# R7FA6T3BB register map
Vendor: Renesas Electronics Corporation; Series: RA6; File version: 1.30.00
CPU: CM33 r0p4, little endian, MPU, FPU, VTOR, 4 interrupt priority bits, 96 interrupts
Registers are 32-bit, read-write, reset 0x0 unless marked. A register's access mark holds for its fields unless they carry their own. Offsets are from the block's base; [hi:lo] are bit positions; 'fields as' and 'values as' point back to an identical list.

## MSTP — Module Stop Control
Base 0x40084000
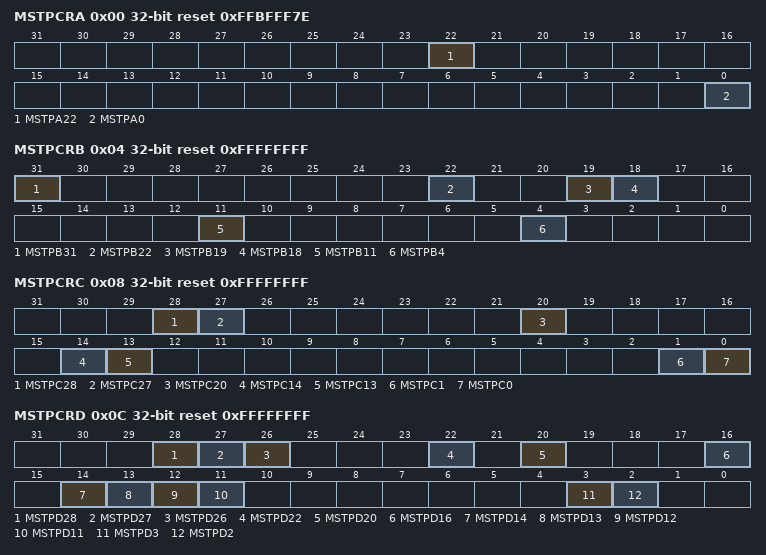
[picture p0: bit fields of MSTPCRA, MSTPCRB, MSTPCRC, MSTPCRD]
0x00 MSTPCRA reset 0xFFBFFF7E — Module Stop Control Register A
  [22] MSTPA22 — DMA Controller/Data Transfer Controller Module Stop
    0=Cancel the module-stop state; 1=Enter the module-stop state
  [0] MSTPA0 — SRAM0 Module Stop
    values as MSTPA22
0x04 MSTPCRB reset 0xFFFFFFFF — Module Stop Control Register B
  [all] fields
    values as MSTPCRA.MSTPA22
  [31] MSTPB31 — Serial Communication Interface 0 Module Stop
  [22] MSTPB22 — Serial Communication Interface 9 Module Stop
  [19] MSTPB19 — Serial Peripheral Interface 0 Module Stop
  [18] MSTPB18 — Serial Peripheral Interface 1 Module Stop
  [11] MSTPB11 — Universal Serial Bus 2.0 FS Interface 0 Module Stop
  [4] MSTPB4 — I3C Bus Interface 0 Module Stop
0x08 MSTPCRC reset 0xFFFFFFFF — Module Stop Control Register C
  [all] fields
    values as MSTPCRA.MSTPA22
  [28] MSTPC28 — Random Number Generator Module Stop
  [27] MSTPC27 — CANFD Module Stop
  [20] MSTPC20 — Trigonometric Function Unit Module Stop
  [14] MSTPC14 — Event Link Controller Module Stop
  [13] MSTPC13 — Data Operation Circuit Module Stop
  [1] MSTPC1 — Cyclic Redundancy Check Calculator Module Stop
  [0] MSTPC0 — Clock Frequency Accuracy Measurement Circuit Module Stop
0x0C MSTPCRD reset 0xFFFFFFFF — Module Stop Control Register D
  [all] fields
    values as MSTPCRA.MSTPA22
  [28] MSTPD28 — High-Speed Analog Comparator 0 Module Stop
  [27] MSTPD27 — High-Speed Analog Comparator 1 Module Stop
  [26] MSTPD26 — High-Speed Analog Comparator 2 Module Stop
  [22] MSTPD22 — Temperature Sensor Module Stop
  [20] MSTPD20 — 12-bit D/A Converter Module Stop
  [16] MSTPD16 — 12-bit A/D Converter 0 Module Stop
  [14] MSTPD14 — Port Output Enable for GPT Group A Module Stop
  [13] MSTPD13 — Port Output Enable for GPT Group B Module Stop
  [12] MSTPD12 — Port Output Enable for GPT Group C Module Stop
  [11] MSTPD11 — Port Output Enable for GPT Group D Module Stop
  [3] MSTPD3 — Low Power Asynchronous General Purpose Timer 0 Module Stop
  [2] MSTPD2 — Low Power Asynchronous General Purpose Timer 1 Module Stop
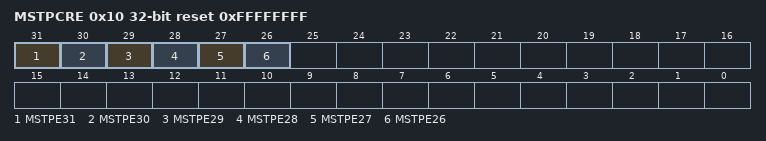
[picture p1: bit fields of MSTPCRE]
0x10 MSTPCRE reset 0xFFFFFFFF — Module Stop Control Register E
  [all] fields
    values as MSTPCRA.MSTPA22
  [31] MSTPE31 — GPT0 Module Stop
  [30] MSTPE30 — GPT1 Module Stop
  [29] MSTPE29 — GPT2 Module Stop
  [28] MSTPE28 — GPT3 Module Stop
  [27] MSTPE27 — GPT4 Module Stop
  [26] MSTPE26 — GPT5 Module Stop

## TSN — Temperature Sensor
Base 0x400F3000
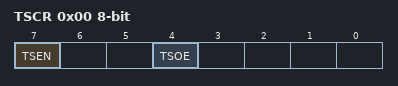
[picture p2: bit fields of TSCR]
0x00 TSCR 8-bit — Temperature Sensor Control Register
  [7] TSEN — Temperature Sensor Enable
    0=Stop the temperature sensor; 1=Start the temperature sensor
  [4] TSOE — Temperature Sensor Output Enable
    0=Disable output from the temperature sensor to the ADC12; 1=Enable output from the temperature sensor to the ADC12

## ACMPHS0 — High-Speed Analog Comparator 0
Base 0x400F4000
Same registers: ACMPHS1 0x400F4100, ACMPHS2 0x400F4200
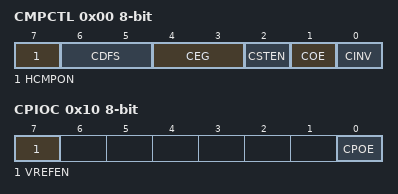
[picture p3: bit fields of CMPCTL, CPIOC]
0x00 CMPCTL 8-bit — Comparator Control Register
  [7] HCMPON — Comparator Operation Control
    0=Stop operation (comparator outputs a low-level signal); 1=Enable operation (enables input to the comparator pins)
  [6:5] CDFS — Noise Filter Selection
    0=Do not use noise filter; 1=Use noise filter sampling frequency of PCLKB/23; 2=Use noise filter sampling frequency of PCLKB/24; 3=Use noise filter sampling frequency of PCLKB/25
  [4:3] CEG — Selection of Valid Edge (Edge Selector)
    0=Do not detect edge; 1=Detect rising edge; 2=Detect falling edge; 3=Detect both edges
  [2] CSTEN — Interrupt Select
    0=Output through the edge selector; 1=Output directly
  [1] COE — Comparator Output Enable
    0=Disable comparator output (output signal is low level); 1=Enable comparator output
  [0] CINV — Comparator Output Polarity Selection
    0=Do not invert comparator output; 1=Invert comparator output
0x04 CMPSEL0 8-bit — Comparator Input Select Register
  [3:0] CMPSEL — Comparator Input Selection
    0=Do not input; 1=Select IVCMP0; 2=Select IVCMP1; 4=Select IVCMP2; 8=Select IVCMP3; other=Others (Setting prohibited)
0x08 CMPSEL1 8-bit — Comparator Reference Voltage Select Register
  [3:0] CRVS — Reference Voltage Selection
    0=Do not input; 1=Select IVREF0; 2=Select IVREF1; 4=Select IVREF2; 8=Select IVREF3; other=Others (Setting prohibited)
0x0C CMPMON 8-bit ro — Comparator Output Monitor Register
  [0] CMPMON — Comparator Output Monitor
    0=Comparator output is low; 1=Comparator output is high
0x10 CPIOC 8-bit — Comparator Output Control Register
  [7] VREFEN — VREFEN Internal Vref Enable
    0=Disable internal Vref; 1=Enable internal Vref
  [0] CPOE — Comparator Output Selection
    0=Disable CMPOUTn pin output of the comparator (output signal is low fixed); 1=Enable CMPOUTn pin output of the comparator
